# CC2753 register map
File version: 1.0
CPU: CM0+ r0p4, little endian, no MPU, no FPU, VTOR, 3 interrupt priority bits
Registers are 32-bit, read-write, reset 0x0 unless marked. A register's access mark holds for its fields unless they carry their own. Offsets are from the block's base; [hi:lo] are bit positions; {n}, {i} and the like mark numbered series.

## I2S — I2S Audio DMA module supporting formats I2S, LJF, RJF and DSP
Base 0x400C1000
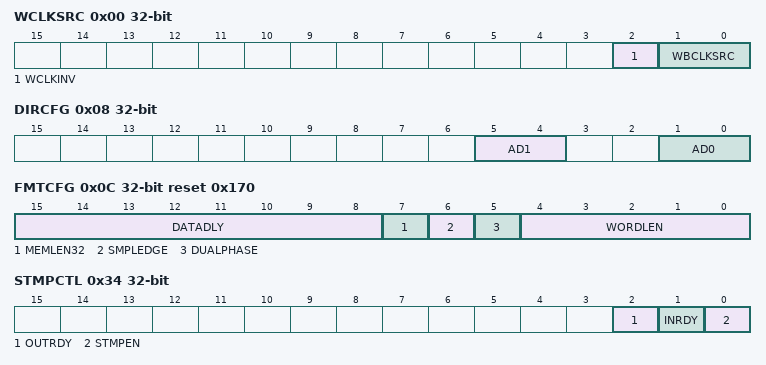
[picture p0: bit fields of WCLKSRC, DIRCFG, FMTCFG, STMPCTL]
0x00 WCLKSRC — This register configures the WCLK Source
  [2] WCLKINV — This field Inverts WCLK source (pad or internal).
    1=INVERTED (Source is inverted); 0=NOT_INTVERTED (Source is not intverted)
  [1:0] WBCLKSRC — This field selects WCLK/BCLK source for I2S.
    3=RESERVED (Not supported. Will give same WCLK as 'NONE' ('00')); 2=INT (Internal WCLK generator, from module PRCM); 1=EXT (External WCLK generator, from pad); 0=NONE (None ('0'))
0x04 DMACFG — This register configures DMA buffer size
  [7:0] ENDFRMIDX — This field defines the length of the DMA buffer. Writing a non-zero value to this register field enables and initializes I2S. Note that before doing so, all other configuration must have been done, and INPTRNXT/OUTPTRNXT must have been loaded.
0x08 DIRCFG — This register configures the direction of data pins(AD0/AD1)
  [5:4] AD1 — The field configures the AD1 data pin direction
    2=OUT (Output); 1=IN (Input); 0=DIS (Not in use (disabled))
  [1:0] AD0 — The field configures the AD0 data pin direction
    2=OUT (Output); 1=IN (Input); 0=DIS (Not in use (disabled))
0x0C FMTCFG reset 0x170 — This register configures the serial interface format
  [15:8] DATADLY — This field configures the number of BCLK periods between a WCLK edge and MSB of the first word in a phase Note: When 0, MSB of the next word will be output in the idle period between LSB of the previous word and the start of the next word. Otherwise logical 0 will be output until the data delay has expired.
    255=MAX (Max(255) BCLK periods - RJF format); 2=TWO (Two(Min) BCLK periods - RJF format); 1=ONE (One BCLK periods - I2S and DSP formats); 0=ZERO (Zero BCLK periods - LJF and DSP formats)
  [7] MEMLEN32 — This register configures the size of each word stored to or loaded from memory
    1=EN (32-bit(one 32-bit access per sample)); 0=DIS (16-bit (one 16 bit access per sample))
  [6] SMPLEDGE — This field configures the sample edge/ transfer edge of data (and WCLK) on BCLK
    1=POSEDGE (Data is sampled on the positive edge and clocked out on the negative edge.); 0=NEGEDGE (Data is sampled on the negative edge and clocked out on the positive edge.)
  [5] DUALPHASE — This field selects between dual-phase or single-phase format
    1=DUALPHASE (Dual-phase: I2S, LJF and RJF formats); 0=SINGLEPHASE (Single-phase: DSP format)
  [4:0] WORDLEN — Number of bits per word (8-24): In single-phase format, this is the exact number of bits per word. In dual-phase format, this is the maximum number of bits per word. Values below 8 and above 24 give undefined behavior. Data written to memory is always aligned to 16 or 24 bits as defined by MEMLEN32. Bit widths that differ from this alignment will either be truncated or zero padded.
0x10 WMASK0 reset 0x3 — This register configures the word selection dit mask for data pin 0(AD0)
  [7:0] MASK — Bit-mask indicating valid channels in a frame on AD0. In single-phase mode, each bit represents one channel, starting with LSB for the first word in the frame. A frame can contain up to 8 channels. Channels that are not included in the mask will not be sampled and stored in memory, and clocked out as '0'. In dual-phase mode, only the two LSBs are considered. For a stereo configuration, set both bits. For a mono configuration, set bit 0 only. In mono mode, only channel 0 will be sampled and stored to memory, and channel 0 will be repeated when clocked out. In mono mode, only channel 0 will be sampled and stored to memory, and channel 0 will be repeated in the second phase when clocked out. If all bits are zero, no input words will be stored to memory, and the output data lines will be constant '0'. This can be utilized when PWM debug output is desired without any actively used output pins.
0x14 WMASK1 reset 0x3 — This register configures the word selection dit mask for data pin 1(AD1)
  [7:0] MASK — Bit-mask indicating valid channels in a frame on AD1. In single-phase mode, each bit represents one channel, starting with LSB for the first word in the frame. A frame can contain up to 8 channels. Channels that are not included in the mask will not be sampled and stored in memory, and clocked out as '0'. In dual-phase mode, only the two LSBs are considered. For a stereo configuration, set both bits. For a mono configuration, set bit 0 only. In mono mode, only channel 0 will be sampled and stored to memory, and channel 0 will be repeated when clocked out. In mono mode, only channel 0 will be sampled and stored to memory, and channel 0 will be repeated in the second phase when clocked out. If all bits are zero, no input words will be stored to memory, and the output data lines will be constant '0'. This can be utilized when PWM debug output is desired without any actively used output pins.
0x20 INPTRNXT — This register configures DMA input buffer next pointer
  [31:0] PTR — Pointer to the first byte in the next DMA input buffer. The read value equals the last written value until the currently used DMA input buffer is completed, and then becomes null when the last written value is transferred to the DMA controller to start on the next buffer. This event is signalized by IRQFLAGS.DMAIN. At startup, the value must be written once before and once after configuring the DMA buffer size in DMACFG. The next pointer must be written to this register while the DMA function uses the previously written pointer. If not written in time, IRQFLAGS.PTRERR will be raised and all input pins will be disabled.
0x24 INPTR — This register configures the DMA input buffer current pointer
  [31:0] PTR ro — Value of the DMA input buffer pointer currently used by the DMA controller. Incremented by 1 (byte) or 2 (word) for each AHB access.
0x28 OUTPTRNXT — This register configures DMA output buffer next pointer
  [31:0] PTR — Pointer to the first byte in the next DMA output buffer. The read value equals the last written value until the currently used DMA output buffer is completed, and then becomes null when the last written value is transferred to the DMA controller to start on the next buffer. This event is signalized by IRQFLAGS.DMAOUT. At startup, the value must be written once before and once after configuring the DMA buffer size in DMACFG. At this time, the first two samples will be fetched from memory. The next pointer must be written to this register while the DMA function uses the previously written pointer. If not written in time, IRQFLAGS.PTRERR will be raised and all output pins will be disabled.
0x2C OUTPTR — This register configures DMA output buffer current pointer
  [31:0] PTR ro — Value of the DMA output buffer pointer currently used by the DMA controller Incremented by 1 (byte) or 2 (word) for each AHB access.
0x34 STMPCTL — This register controls the samplestamp generator.
  [2] OUTRDY ro — This field is low until the output pins are ready to be started by the samplestamp generator. When started (that is STMPOUTTRIG equals the WCLK counter) the bit goes back low.
  [1] INRDY ro — This field is low until the input pins are ready to be started by the samplestamp generator. When started (that is STMPINTRIG equals the WCLK counter) the bit goes back low.
  [0] STMPEN — This field configures the samplestamp generator. The samplestamp generator must only be enabled after it has been properly configured. When cleared, all samplestamp generator counters and capture values are cleared.
    1=EN (Enable the samplestamp generator); 0=DIS (Disable the samplestamp generator)
0x38 STMPXCNTCAPT0 ro — This register gives the captured XOSC counter value, capture channel 0
  [15:0] CAPTVALUE — The value of the samplestamp XOSC counter (STMPXCNT.CURRVALUE) last time an event was pulsed. This number corresponds to the number of 24 MHz clock cycles since the last positive edge of the selected WCLK. The value is cleared when STMPCTL.STMPEN = 0. Note: Due to buffering and synchronization, WCLK is delayed by a small number of BCLK periods and clk periods. Note: When calculating the fractional part of the sample stamp, STMPXPER may be less than this bit field.
0x3C STMPXPER ro — The register gives the XOSC period value
  [15:0] VALUE — The number of 24 MHz clock cycles in the previous WCLK period (that is - the next value of the XOSC counter at the positive WCLK edge, had it not been reset to 0). The value is cleared when STMPCTL.STMPEN = 0.
0x40 STMPWCNTCAPT0 ro — This register gives the captured WCLK counter value, capture channel 0
  [15:0] CAPT_VALUE — The value of the samplestamp WCLK counter (STMPWCNT.CURRVALUE) last time an event was pulsed. This number corresponds to the number of positive WCLK edges since the samplestamp generator was enabled (not taking modification through STMPWADD/STMPWSET into account). The value is cleared when STMPCTL.STMPEN = 0.
0x44 STMPWPER — This register configures WCLK counter period value
  [15:0] VALUE — This field defines when STMPWCNT is to be reset so number of WCLK edges are found for the size of the sample buffer. This is thus a modulo value for the WCLK counter. This number must correspond to the size of the sample buffer used by the system (that is the index of the last sample plus 1).
0x48 STMPINTRIG — This register configures WCLK counter trigger value for input pins
  [15:0] INSTARTWCNT — This field configures the compare value used to start the incoming audio streams. This bit field shall equal the WCLK counter value during the WCLK period in which the first input word(s) are sampled and stored to memory (that is the sample at the start of the very first DMA input buffer). The value of this register takes effect when the following conditions are met: - One or more pins are configured as inputs in DIRCFG. - DMACFG has been configured for the correct buffer size, and at least 32 BCLK cycle ticks have happened. Note: To avoid false triggers, this bit field should be set higher than STMPWPER.VALUE.
0x4C STMPOUTTRIG — This register configures WCLK counter trigger value for output pins
  [15:0] OUTSTARTWCNT — This field cofnigures the compare value used to start the outgoing audio streams. This bit field must equal the WCLK counter value during the WCLK period in which the first output word(s) read from memory are clocked out (that is the sample at the start of the very first DMA output buffer). The value of this register takes effect when the following conditions are met: - One or more pins are configured as outputs in DIRCFG. - DMACFG has been configured for the correct buffer size, and 32 BCLK cycle ticks have happened. - 2 samples have been preloaded from memory (examine the OUTPTR register if necessary). Note: The memory read access is only performed when required, that is channels 0/1 must be selected in WMASK0/WMASK1. Note: To avoid false triggers, this bit field should be set higher than STMPWPER.VALUE.
0x50 STMPWSET — This register confiures WCLK counter set operation
  [15:0] VALUE wo — Sets the running WCLK counter equal to the written value.
0x54 STMPWADD — This register configures WCLK counter add operation
  [15:0] VALUEINC wo — Adds the written value to the running WCLK counter. If a positive edge of WCLK occurs at the same time as the operation, this will be taken into account. To add a negative value, write "STMPWPER.VALUE - value".
0x58 STMPXPERMIN reset 0xFFFF — This register configures XOSC minimum period value Minimum Value of STMPXPER
  [15:0] VALUE — Each time STMPXPER is updated, the value is also loaded into this register, provided that the value is smaller than the current value in this register. When written, the register is reset to 0xFFFF (65535), regardless of the value written. The minimum value can be used to detect extra WCLK pulses (this registers value will be significantly smaller than STMPXPER.VALUE).
0x5C STMPWCNT ro — This register gives the current value of WLCK counter
  [15:0] CURRVALUE — Current value of the WCLK counter
0x60 STMPXCNT ro — This register gives the current value XOSC counter
  [15:0] CURRVALUE — Current value of the XOSC counter, latched when reading STMPWCNT.
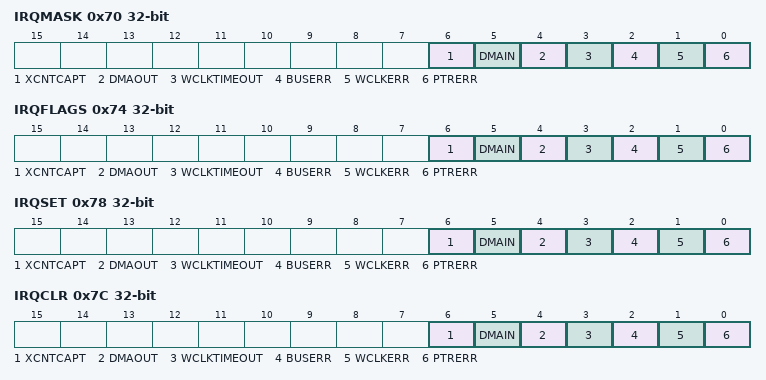
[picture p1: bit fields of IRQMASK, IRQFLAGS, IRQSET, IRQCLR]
0x70 IRQMASK — Interrupt Mask Register Selects mask states of the flags in IRQFLAGS that contribute to the I2S_IRQ event.
  [all] fields
    1=EN (Enable the interrupt mask); 0=DIS (Disable the interrupt mask)
  [6] XCNTCAPT — IRQFLAGS.XCNTCAPT interrupt mask
  [5] DMAIN — IRQFLAGS.DMAIN interrupt mask
  [4] DMAOUT — IRQFLAGS.DMAOUT interrupt mask
  [3] WCLKTIMEOUT — IRQFLAGS.WCLKTIMEOUT interrupt mask
  [2] BUSERR — IRQFLAGS.BUSERR interrupt mask
  [1] WCLKERR — IRQFLAGS.WCLKERR interrupt mask
  [0] PTRERR — IRQFLAGS.PTRERR interrupt mask.
0x74 IRQFLAGS ro — This registers gives the raw interrupt status
  [all] fields
    1=SET (Interrupt occured); 0=CLR (Interrupt did not occur)
  [6] XCNTCAPT — This interrupt is set when xcnt counter is captured either by events or software. Needs to be cleared by software.
  [5] DMAIN — This interrupt is set when condition for this bit field event occurs (auto cleared when input pointer is updated - AIFINPTRNEXT), see description of AIFINPTRNEXT register for details.
  [4] DMAOUT — This interrupt is set when condition for this bit field event occurs (auto cleared when output pointer is updated - OUTPTRNXT), see description of OUTPTRNXT register for details
  [3] WCLKTIMEOUT — Set when the sample stamp generator does not detect a positive WCLK edge for 65535 clk periods. This signalizes that the internal or external BCLK and WCLK generator source has been disabled. The bit is sticky and may only be cleared by software (by writing '1' to IRQCLR.WCLKTIMEOUT).
  [2] BUSERR — This interrupt set when a DMA operation is not completed in time (that is audio output buffer underflow, or audio input buffer overflow). This error requires a complete restart since word synchronization has been lost. The bit is sticky and may only be cleared by software (by writing '1' to IRQCLR.BUSERR). Note that DMA initiated transactions to illegal addresses will not trigger an interrupt. The response to such transactions is undefined.
  [1] WCLKERR — This interrupt is set when: - An unexpected WCLK edge occurs during the data delay period of a phase. Note unexpected WCLK edges during the word and idle periods of the phase are not detected. - In dual-phase mode, when two WCLK edges are less than 4 BCLK cycles apart. - In single-phase mode, when a WCLK pulse occurs before the last channel. This error requires a complete restart since word synchronization has been lost. The bit is sticky and may only be cleared by software (by writing '1' to IRQCLR.WCLKERR).
  [0] PTRERR — This interrupt set when INPTRNXT or OUTPTRNXT has not been loaded with the next block address in time. This error requires a complete restart since word synchronization has been lost. The bit is sticky and may only be cleared by software (by writing '1' to IRQCLR.PTRERR).
0x78 IRQSET wo — Interrupt Set Register. This register can be used by software for diagnostics and safety checking purposes.
  [all] fields
    1=SET (Set interrupt); 0=NOEFF (Writing 0 has no effect)
  [6] XCNTCAPT — This field sets the interrupt IRQFLAGS.XCNTCAPT (unless a auto clear criteria was given at the same time, in which the set will be ignored)
  [5] DMAIN — This field sets the interrupt IRQFLAGS.DMAIN (unless a auto clear criteria was given at the same time, in which the set will be ignored)
  [4] DMAOUT — This field sets the interrupt IRQFLAGS.DMAOUT (unless a auto clear criteria was given at the same time, in which the set will be ignored)
  [3] WCLKTIMEOUT — This field sets the interrupt IRQFLAGS.WCLKTIMEOUT(unless a auto clear criteria was given at the same time, in which the set will be ignored)
  [2] BUSERR — 1: Sets the interrupt of IRQFLAGS.BUSERR(unless a auto clear criteria was given at the same time, in which the set will be ignored)
  [1] WCLKERR — This field sets the interrupt IRQFLAGS.WCLKERR(unless a auto clear criteria was given at the same time, in which the set will be ignored)
  [0] PTRERR — This field sets the interrupt IRQFLAGS.PTRERR(unless a auto clear criteria was given at the same time, in which the set will be ignored)
0x7C IRQCLR wo — Interrupt clear register. This register allows software to clear interrupts.
  [all] fields
    1=CLR (Clear interrupt); 0=NOEFF (Writing 0 has no effect)
  [6] XCNTCAPT — Ths field clears the interrupt IRQFLAGS.XCNTCAPT (unless a set criteria was given at the same time in which the clear will be ignored)
  [5] DMAIN — This field clears the interrupt of IRQFLAGS.DMAIN (unless a set criteria was given at the same time in which the clear will be ignored)
  [4] DMAOUT — This field clears the interrupt IRQFLAGS.DMAOUT (unless a set criteria was given at the same time in which the clear will be ignored)
  [3] WCLKTIMEOUT — 1: Clears the interrupt of IRQFLAGS.WCLKTIMEOUT (unless a set criteria was given at the same time in which the clear will be ignored)
  [2] BUSERR — This field clears the interrupt IRQFLAGS.BUSERR (unless a set criteria was given at the same time in which the clear will be ignored)
  [1] WCLKERR — This field clears the interrupt IRQFLAGS.WCLKERR (unless a set criteria was given at the same time in which the clear will be ignored)
  [0] PTRERR — This field clears the interrupt IRQFLAGS.PTRERR (unless a set criteria was given at the same time in which the clear will be ignored)
0x80 MCLKDIV — This field configures MCLK division ratio
  [9:0] MDIV — An unsigned factor of the division ratio used to generate MCLK [2-1024]: MCLK = MCUCLK/MDIV[Hz] MCUCLK is upto 96MHz. A value of 0 is interpreted as 1024. A value of 1 is invalid. If MDIV is odd the low phase of the clock is one MCUCLK period longer than the high phase.
0x84 BCLKDIV — This field configures BCLK division ratio
  [9:0] BDIV — An unsigned factor of the division ratio used to generate BCLK [2-1024]: BCLK = MCUCLK/BDIV[Hz] MCUCLK can be upto 96MHz. A value of 0 is interpreted as 1024. A value of 1 is invalid. If BDIV is odd and FMTCFG.SMPLEDGE = 0, the low phase of the clock is one MCUCLK period longer than the high phase. If BDIV is odd and FMTCFG.SMPLEDGE = 1 , the high phase of the clock is one MCUCLK period longer than the low phase.
0x88 WCLKDIV — This field configures WCLK division ratio
  [15:0] WDIV — If CLKCTL.WCLKPHASE = 0, Single phase. WCLK is high one BCLK period and low WDIV[9:0] (unsigned, [1-1023]) BCLK periods. WCLK = MCUCLK / BDIV*(WDIV[9:0] + 1) [Hz] MCUCLK upto 96MHz. If [CLKCTL.WCLKPHASE.*] = 1, Dual phase. Each phase on WCLK (50% duty cycle) is WDIV[9:0] (unsigned, [1-1023]) BCLK periods. **WCLK **= **MCUCLK **/ BDIV*(2*WDIV[9:0]) [Hz] If [CLKCTL.WCLKPHASE.*] = 2, User defined. WCLK is high WDIV[7:0] (unsigned, [1-255]) BCLK periods and low WDIV[15:8] (unsigned, [1-255]) BCLK periods. WCLK = **MCUCLK **/ (BDIV*(WDIV[7:0] + WDIV[15:8]) [Hz]
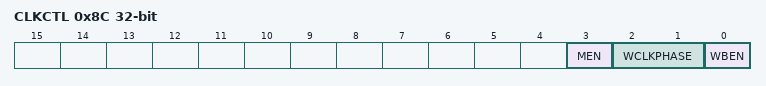
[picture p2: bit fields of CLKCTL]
0x8C CLKCTL — This register controls internal audio clock
  [3] MEN — This field configures the MCLK generation
    1=EN (Enable the generation); 0=DIS (Disable the generation)
  [2:1] WCLKPHASE — The field configures how the WCLK division ratio is calculated and used to generate different duty cycles (See WCLKDIV.WDIV)
  [0] WBEN — This field configures WCLK/BCLK generation
    1=EN (Enable the generation); 0=DIS (Disables the generation)
0x90 DTB — Digital test bus control
  [1:0] SEL — The field controls the select of DTB
    3={12{1'b0},aif_words_sampled, aif_word_loaded, aif_output_en, aif_input_en}; 2=Samplestamp XCNT(16 bits); 1=Samplestamp WCNT(16 bits); 0=None is selected
